# MSS_MCAN_ECC register map
Vendor: Texas Instruments
Peripheral module from a debugger description file (folder am273).
Registers are 32-bit, access per field, no defined reset value unless marked. A register's access mark holds for its fields unless they carry their own. Offsets are as the file gives them; lines under a group give offsets from that group; [hi:lo] are bit positions; {n}, {i} and the like mark numbered series; 'fields as' and 'values as' point back to an identical list; <NAME> marks a mode.

## MSS_MCAN_ECC
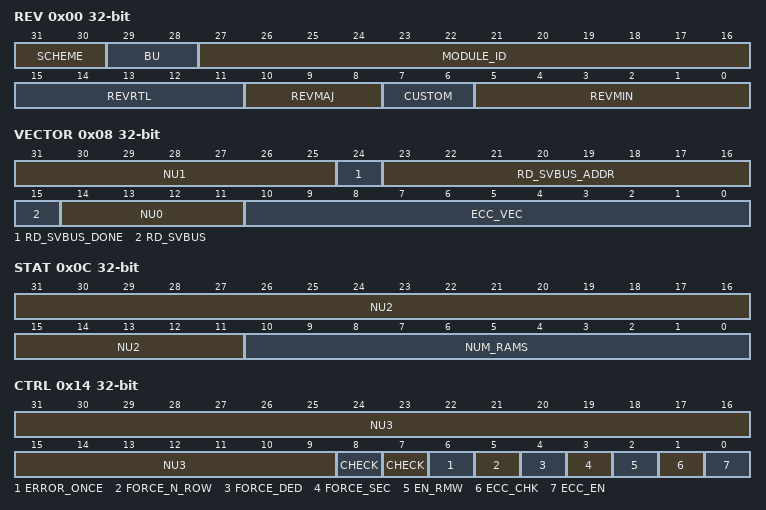
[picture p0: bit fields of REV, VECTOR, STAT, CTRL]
0x00 REV ro — Aggregator Revision Register
  [31:30] SCHEME
  [29:28] BU
  [27:16] MODULE_ID
  [15:11] REVRTL — RTL version
  [10:8] REVMAJ — Major version
  [7:6] CUSTOM — Custom version
  [5:0] REVMIN — Minor version
0x08 VECTOR — ECC Vector Register
  [31:25] NU1 ro — Reserved
  [24] RD_SVBUS_DONE rw — Status to indicate if read on serial VBUS is complete, write of any value will clear this bit. Writing 1 to any bit will clear the corresponding bits. Reads do not alter the value of the field.
  [23:16] RD_SVBUS_ADDR rw — Read address
  [15] RD_SVBUS rw — Write 1 to trigger a read on the serial VBUS. Writing 1 to any bit will set the corresponding bit. Reads do not alter the value of the field.
  [14:11] NU0 ro — Reserved
  [10:0] ECC_VEC rw — Value written to select the corresponding ECC RAM for control or status
0x0C STAT ro — Misc Status
  [31:11] NU2 — Reserved
  [10:0] NUM_RAMS — Indicates the number of RAMS serviced by the ECC aggregator
0x14 CTRL
  [31:9] NU3 ro — TI Internal : Reserved
  [8] CHECK TIMEOUT wo — TI Internal : Check timeout
  [7] CHECK PARITY wo — TI Internal : Check Parity
  [6] ERROR_ONCE wo — TI Internal : Force Error only once
  [5] FORCE_N_ROW wo — TI Internal : Force Error on any RAM read
  [4] FORCE_DED wo — TI Internal : Force Double Bit Error
  [3] FORCE_SEC wo — TI Internal : Force Single Bit Error
  [2] EN_RMW wo — TI Internal : Enable rmw
  [1] ECC_CHK wo — TI Internal : Enable ECC check
  [0] ECC_EN wo — TI Internal : Enable ECC
0x18 ERR_CTRL1 rw
  [31:0] ECC_ROW — TI Internal : Row address where single or double-bit error needs to be applied. This is ignored if force_n_row is set
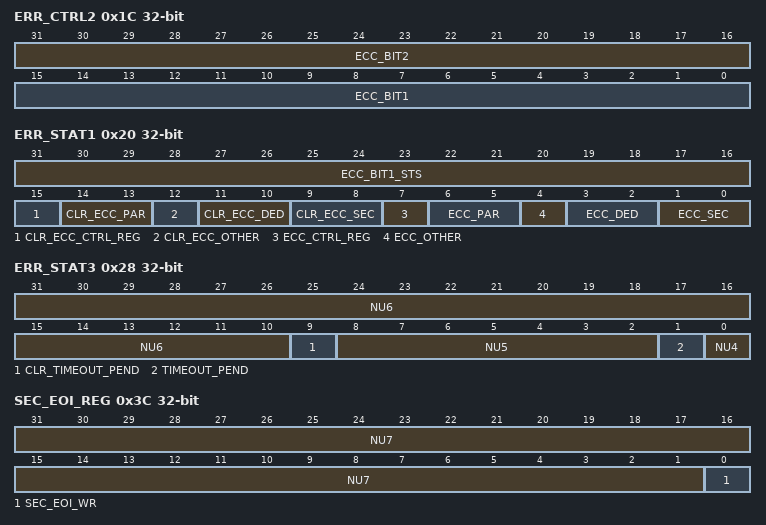
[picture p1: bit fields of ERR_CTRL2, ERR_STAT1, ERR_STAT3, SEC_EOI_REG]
0x1C ERR_CTRL2 rw
  [31:16] ECC_BIT2 — TI Internal : Data bit that needs to be flipped if double bit error needs to be forced
  [15:0] ECC_BIT1 — TI Internal : Data bit that needs to be flipped when force_sec is set
0x20 ERR_STAT1
  [31:16] ECC_BIT1_STS ro — TI Internal : Data bit that corresponds to the single-bit error
  [15] CLR_ECC_CTRL_REG wo — TI Internal : Clear Ctrl Reg Error Status. Write 1 to clear. This bit is self clearing.
  [14:13] CLR_ECC_PAR wo — TI Internal : Clear Parity Error Status. Write 1 to clear. This bit is self clearing.
  [12] CLR_ECC_OTHER wo — TI Internal : Clear Other Error Status. Write 1 to clear. This bit is self clearing.
  [11:10] CLR_ECC_DED wo — TI Internal : Clear Double Bit Error Status. Write 1 to clear. This bit is self clearing.
  [9:8] CLR_ECC_SEC wo — TI Internal : Clear Single Bit Error Status. Write 1 to clear. This bit is self clearing.
  [7] ECC_CTRL_REG wo — TI Internal : Force ctrl reg pending interrupt. Write 1 to set. This bit is self clearing.
  [6:5] ECC_PAR wo — TI Internal : Force ECC parity pending interrupt. Write 1 to set. This bit is self clearing.
  [4] ECC_OTHER wo — TI Internal : Force ECC other pending interrupt. Write 1 to set. This bit is self clearing.
  [3:2] ECC_DED wo — TI Internal : Force ECC DED pending interrupt. Write 1 to set. This bit is self clearing.
  [1:0] ECC_SEC wo — TI Internal : Force ECC SEC pending interrupt. Write 1 to set. This bit is self clearing.
0x24 ERR_STAT2 ro
  [31:0] ECC_ROW — TI Internal : Row address where the single or double-bit error has occurred
0x28 ERR_STAT3
  [31:10] NU6 ro — TI Internal : Reserved
  [9] CLR_TIMEOUT_PEND wo — TI Internal : Clear timeout pending
  [8:2] NU5 ro — TI Internal : Reserved
  [1] TIMEOUT_PEND wo — TI Internal : Timeout pending
  [0] NU4 ro — TI Internal : Reserved
0x3C SEC_EOI_REG — EOI Register
  [31:1] NU7 ro — Reserved
  [0] SEC_EOI_WR rw — EOI Register. Writing 1 to any bit will set the corresponding bit. Reads do not alter the value of the field. This bit is self clearing, reading this bit will return 0.
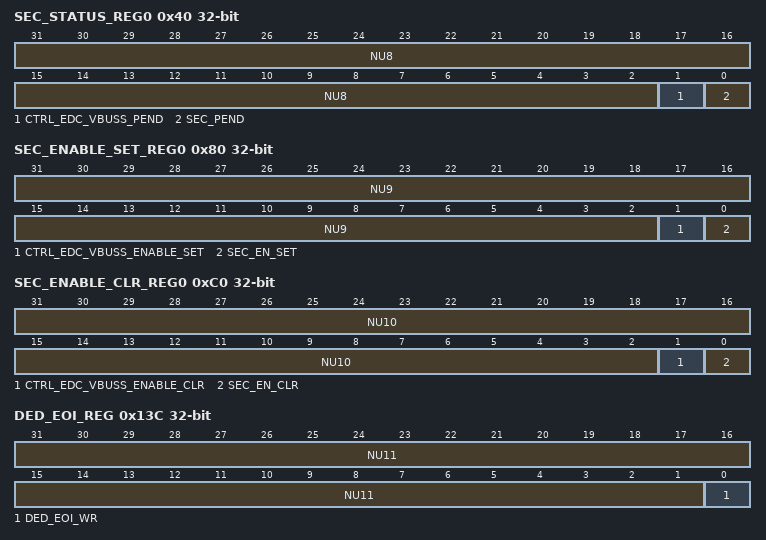
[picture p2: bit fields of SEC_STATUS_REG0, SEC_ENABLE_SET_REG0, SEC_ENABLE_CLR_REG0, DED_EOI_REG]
0x40 SEC_STATUS_REG0 ro — Interrupt Status Register 0
  [31:2] NU8 — Reserved
  [1] CTRL_EDC_VBUSS_PEND — Interrupt Pending Status for ctrl_edc_vbuss_pend.
  [0] SEC_PEND — Interrupt Pending Status for msgmem_pend.
0x80 SEC_ENABLE_SET_REG0 — Interrupt Enable Set Register 0
  [31:2] NU9 ro — Reserved
  [1] CTRL_EDC_VBUSS_ENABLE_SET rw — Interrupt Enable Set Register for ctrl_edc_vbuss_pend. Writing 1 to any bit will set the corresponding bit. Reads do not alter the value of the field.
  [0] SEC_EN_SET rw — Interrupt Enable Set Register for msgmem_pend. Writing 1 to any bit will set the corresponding bit. Reads do not alter the value of the field.
0xC0 SEC_ENABLE_CLR_REG0 — Interrupt Enable Clear Register 0
  [31:2] NU10 ro — Reserved
  [1] CTRL_EDC_VBUSS_ENABLE_CLR rw — Interrupt Enable Clear Register for ctrl_edc_vbuss_pend. Writing 1 to any bit will clear the corresponding bits. Reads do not alter the value of the field. Reading this bit will return 0.
  [0] SEC_EN_CLR rw — Interrupt Enable Clear Register for msgmem_pend. Writing 1 to any bit will clear the corresponding bits. Reads do not alter the value of the field. Reading this bit will return 0.
0x13C DED_EOI_REG — EOI Register
  [31:1] NU11 ro — Reserved
  [0] DED_EOI_WR rw — EOI Register. Writing 1 to any bit will set the corresponding bit. Reads do not alter the value of the field. This bit is self clearing, reading this bit will return 0.
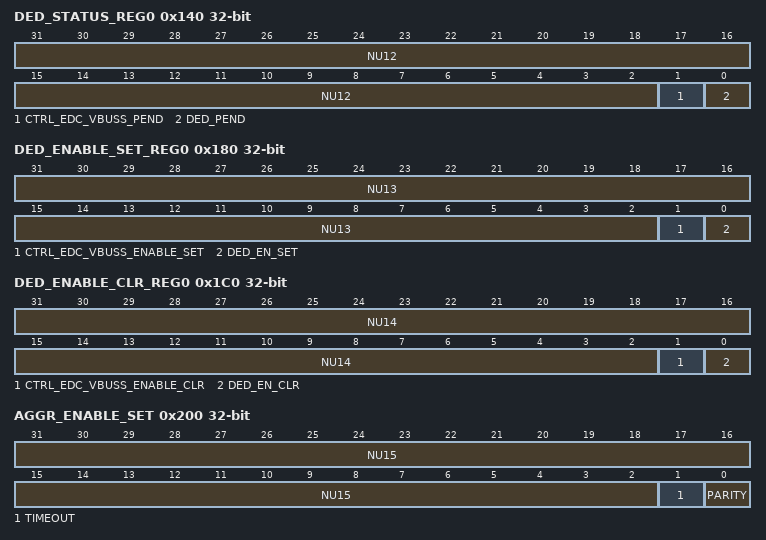
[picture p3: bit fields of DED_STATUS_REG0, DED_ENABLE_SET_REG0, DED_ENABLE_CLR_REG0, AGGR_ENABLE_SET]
0x140 DED_STATUS_REG0 ro — Interrupt Status Register 0
  [31:2] NU12 — Reserved
  [1] CTRL_EDC_VBUSS_PEND — Interrupt Pending Status for ctrl_edc_vbuss_pend.
  [0] DED_PEND — Interrupt Pending Status for msgmem_pend.
0x180 DED_ENABLE_SET_REG0 — Interrupt Enable Set Register 0
  [31:2] NU13 ro — Reserved
  [1] CTRL_EDC_VBUSS_ENABLE_SET rw — Interrupt Enable Set Register for ctrl_edc_vbuss_pend. Writing 1 to any bit will set the corresponding bit. Reads do not alter the value of the field.
  [0] DED_EN_SET rw — Interrupt Enable Set Register for msgmem_pend. Writing 1 to any bit will set the corresponding bit. Reads do not alter the value of the field.
0x1C0 DED_ENABLE_CLR_REG0 — Interrupt Enable Clear Register 0
  [31:2] NU14 ro — Reserved
  [1] CTRL_EDC_VBUSS_ENABLE_CLR rw — Interrupt Enable Clear Register for ctrl_edc_vbuss_pend. Writing 1 to any bit will clear the corresponding bits. Reads do not alter the value of the field. Reading this bit will return 0.
  [0] DED_EN_CLR rw — Interrupt Enable Clear Register for msgmem_pend. Writing 1 to any bit will clear the corresponding bits. Reads do not alter the value of the field. Reading this bit will return 0.
0x200 AGGR_ENABLE_SET — AGGR interrupt enable set Register
  [31:2] NU15 ro — Reserved
  [1] TIMEOUT rw — Interrupt Enable Set Register for svbus timeout errors. Writing 1 to any bit will set the corresponding bit. Reads do not alter the value of the field.
  [0] PARITY rw — Interrupt Enable Set Register for parity errors. Writing 1 to any bit will set the corresponding bit. Reads do not alter the value of the field.
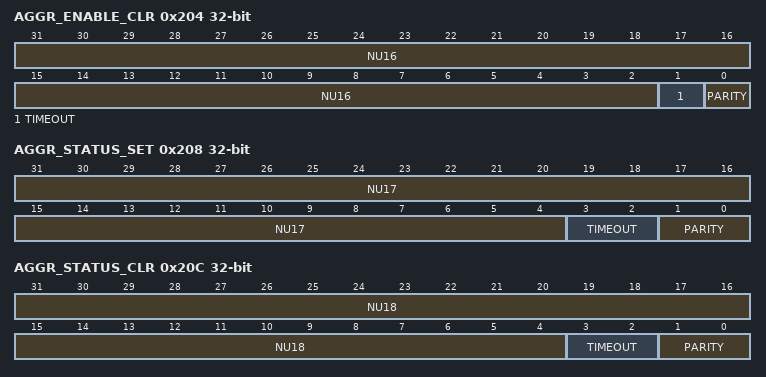
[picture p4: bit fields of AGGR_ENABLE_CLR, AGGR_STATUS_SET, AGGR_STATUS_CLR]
0x204 AGGR_ENABLE_CLR — AGGR interrupt enable clear Register
  [31:2] NU16 ro — Reserved
  [1] TIMEOUT rw — Interrupt Enable Clear for svbus timeout errors. Writing 1 to any bit will clear the corresponding bits. Reads do not alter the value of the field. Reading this bit will return 0.
  [0] PARITY rw — Interrupt Enable Clear for parity errors. Writing 1 to any bit will clear the corresponding bits. Reads do not alter the value of the field. Reading this bit will return 0.
0x208 AGGR_STATUS_SET — AGGR interrupt status set Register
  [31:4] NU17 ro — Reserved
  [3:2] TIMEOUT rw — Interrupt status set for svbus timeout errors. A write to increment field. Writing a value to this field increment the field value by the value written. Reads do not alter the value of the field.
  [1:0] PARITY rw — Interrupt status set for parity errors. A write to increment field. Writing a value to this field increment the field value by the value written. Reads do not alter the value of the field.
0x20C AGGR_STATUS_CLR — AGGR interrupt status clear Register
  [31:4] NU18 ro — Reserved
  [3:2] TIMEOUT rw — Interrupt status clear for svbus timeout errors. A write to decrement field. Writing a value to this field decrements the field value by the value written. Reads do not alter the value of the field.
  [1:0] PARITY rw — Interrupt status clear for parity errors. A write to decrement field. Writing a value to this field decrements the field value by the value written. Reads do not alter the value of the field.
